# EHRPWM0_EPWM register map
Vendor: Texas Instruments
Peripheral module from a debugger description file (folder J7ES).
Registers are 16-bit, access per field, reset 0x0 unless marked. A register's access mark holds for its fields unless they carry their own. Offsets are as the file gives them; lines under a group give offsets from that group; [hi:lo] are bit positions; {n}, {i} and the like mark numbered series; 'fields as' and 'values as' point back to an identical list; <NAME> marks a mode.

## EHRPWM0_EPWM
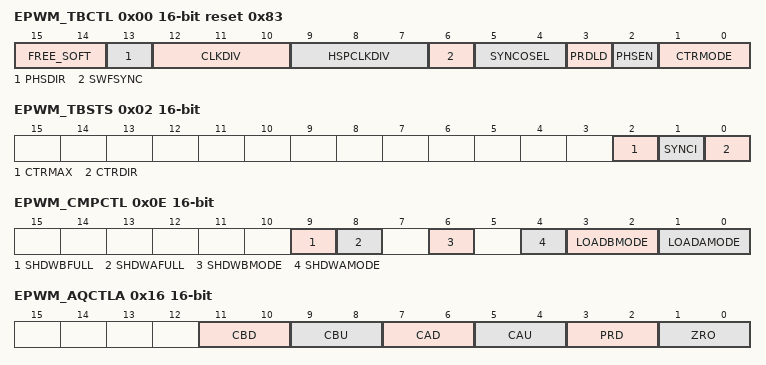
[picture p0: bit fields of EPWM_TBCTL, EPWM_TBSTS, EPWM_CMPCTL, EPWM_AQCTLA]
0x00 EPWM_TBCTL rw reset 0x83
  [15:14] FREE_SOFT, [13] PHSDIR, [12:10] CLKDIV, [9:7] HSPCLKDIV, [6] SWFSYNC, [5:4] SYNCOSEL, [3] PRDLD, [2] PHSEN, [1:0] CTRMODE
0x02 EPWM_TBSTS access not given
  [2] CTRMAX — (access RW1C)
  [1] SYNCI — (access RW1C)
  [0] CTRDIR ro
0x04 HRPWM_TBPHSHR
  [15:8] TBPHSH rw — Time-base phase high-resolution bits
0x06 EPWM_TBPHS rw — This register is only available on ePWM instances that include the high-resolution PWM (HRPWM) extension, otherwise, this location is reserved.
  [15:0] TBPHS — These bits set time-base counter phase of the selected ePWM relative to the time-base that is supplying the synchronization input signal [a] If
0x08 EPWM_TBCNT rw
0x0A EPWM_TBPRD rw
0x0E EPWM_CMPCTL
  [9] SHDWBFULL ro, [8] SHDWAFULL ro, [6] SHDWBMODE rw, [4] SHDWAMODE rw, [3:2] LOADBMODE rw, [1:0] LOADAMODE rw
0x10 HRPWM_CMPAHR — This register is only available on ePWM instances that include the high-resolution PWM (HRPWM) extension; otherwise, this location is reserved.
  [15:8] CMPAHR rw
0x12 EPWM_CMPA rw
0x14 EPWM_CMPB rw
0x16 EPWM_AQCTLA
  [11:10] CBD rw, [9:8] CBU rw, [7:6] CAD rw, [5:4] CAU rw, [3:2] PRD rw, [1:0] ZRO rw
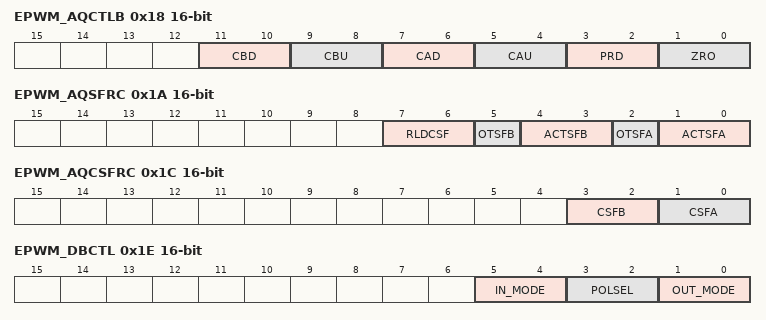
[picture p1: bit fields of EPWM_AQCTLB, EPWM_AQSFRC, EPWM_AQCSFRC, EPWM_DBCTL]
0x18 EPWM_AQCTLB
  fields as EPWM_AQCTLA
0x1A EPWM_AQSFRC access not given
  [7:6] RLDCSF rw
  [5] OTSFB — (access RW1C)
  [4:3] ACTSFB rw
  [2] OTSFA — (access RW1C)
  [1:0] ACTSFA rw
0x1C EPWM_AQCSFRC
  [3:2] CSFB rw, [1:0] CSFA rw
0x1E EPWM_DBCTL
  [5:4] IN_MODE rw, [3:2] POLSEL rw, [1:0] OUT_MODE rw
0x20 EPWM_DBRED
  [9:0] DEL rw — Rising Edge Delay Count. 10-bit counter.
0x22 EPWM_DBFED
  [9:0] DEL rw — Falling Edge Delay Count. 10-bit counter
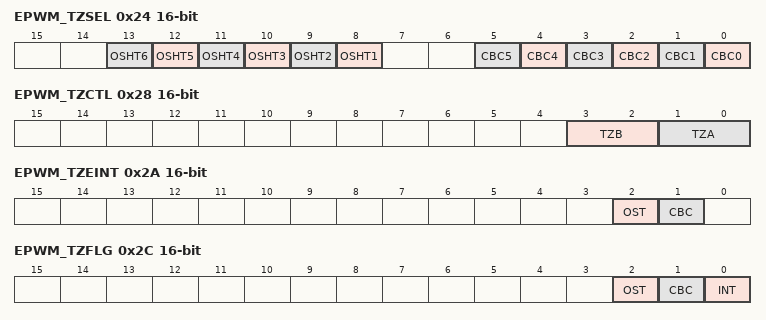
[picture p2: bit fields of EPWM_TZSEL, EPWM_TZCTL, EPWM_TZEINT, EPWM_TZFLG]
0x24 EPWM_TZSEL
  [n+7] OSHT{n} rw (n=1..6), [n] CBC{n} rw (n=0..5)
0x28 EPWM_TZCTL
  [3:2] TZB rw, [1:0] TZA rw
0x2A EPWM_TZEINT
  [2] OST rw — Trip-zone One-Shot Interrupt Enable 0h = Disable one-shot interrupt generation 1h = Enable Interrupt generation
  [1] CBC rw — Trip-zone Cycle-by-Cycle Interrupt Enable 0h = Disable cycle-by-cycle interrupt generation. 1h = Enable interrupt generation
0x2C EPWM_TZFLG ro
  [2] OST, [1] CBC, [0] INT
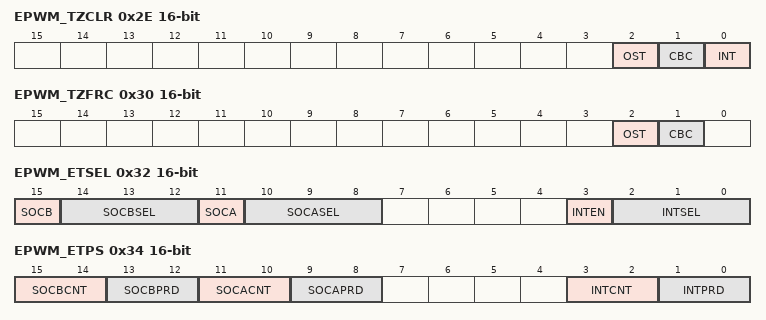
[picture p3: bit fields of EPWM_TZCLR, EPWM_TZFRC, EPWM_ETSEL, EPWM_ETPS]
0x2E EPWM_TZCLR
  [2] OST rw, [1] CBC rw, [0] INT rw
0x30 EPWM_TZFRC
  [2] OST rw, [1] CBC rw
0x32 EPWM_ETSEL
  [15] SOCB rw — Enable SOCB pulse when set to 1.
  [14:12] SOCBSEL rw — EPWMxSOCB Selection Options: 0h: Reserved 1h: Enable event time-base counter equal to zero (CNT_zero event). 2h: Enable event time-base counter equal to period (PRD_eq event). 3h: Reserved 4h: Enable event time-base counter equal to CMPA when the timer is incrementing (CMPA_eq_UC event). 5h: Enable event time-base counter equal to CMPA when the timer is decrementing (CMPA_eq_DC event). 6h: Enable event time-base counter equal to CMPB when the timer is incrementing (CMPB_eq_UC event). 7h: Enable event time-base counter equal to CMPB when the timer is decrementing (CMPB_eq_DC event).
  [11] SOCA rw — Enable SOCA pulse when set to 1.
  [10:8] SOCASEL rw — EPWMxSOCA Selection Options: 0h: Reserved 1h: Enable event time-base counter equal to zero (CNT_zero event). 2h: Enable event time-base counter equal to period (PRD_eq event). 3h: Reserved 4h: Enable event time-base counter equal to CMPA when the timer is incrementing (CMPA_eq_UC event). 5h: Enable event time-base counter equal to CMPA when the timer is decrementing (CMPA_eq_DC event). 6h: Enable event time-base counter equal to CMPB when the timer is incrementing (CMPB_eq_UC event). 7h: Enable event time-base counter equal to CMPB when the timer is decrementing (CMPB_eq_DC event).
  [3] INTEN rw
  [2:0] INTSEL rw
0x34 EPWM_ETPS
  [15:14] SOCBCNT ro — EPWMxSOCB Counter Register: These bits indicate how many selected events have occurred: 0h: No events 1h: 1 events 2h: 2 events 3h: 3 event
  [13:12] SOCBPRD rw — EPWMxSOCB Period Select: These bits select how many selected event need to occur before an SOCB pulse is generated: 0h: Disable counter 1h: Generate pulse on SOCBCNT = 1 (1st event) 2h: Generate pulse on SOCBCNT = 2 (2nd event) 3h: Generate pulse on SOCBCNT = 3 (3rd event)
  [11:10] SOCACNT ro — EPWMxSOCA Counter Register: These bits indicate how many selected events have occurred: 0h: No events 1h: 1 events 2h: 2 events 3h: 3 events
  [9:8] SOCAPRD rw — EPWMxSOCA Period Select: These bits select how many selected event need to occur before an SOCA pulse is generated: 0h: Disable counter 1h: Generate pulse on SOCACNT = 1 (1st event) 2h: Generate pulse on SOCACNT = 2 (2nd event) 3h: Generate pulse on SOCACNT = 3 (3rd event)
  [3:2] INTCNT ro
  [1:0] INTPRD rw
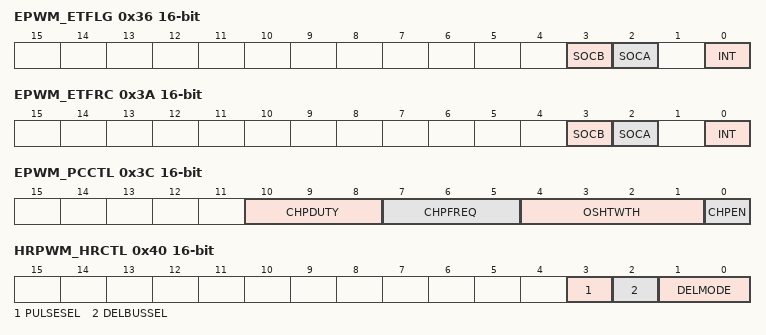
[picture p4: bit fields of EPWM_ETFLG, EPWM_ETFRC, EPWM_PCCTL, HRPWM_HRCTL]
0x36 EPWM_ETFLG ro
  [3] SOCB — Latched SOCB Flag Bit Status: 0h: Indicates no event occurred. 1h: Indicates that a start of conversion pulse was generated on EPWMxSOCB. Note: Unlike the INT flag bit, the EPWMxSOCB output will continue to pulse even if the flag bit is set.
  [2] SOCA — Latched SOCA Flag Bit Status: 0h: Indicates no event occurred. 1h: Indicates that a start of conversion pulse was generated on EPWMxSOCA. Note: Unlike the INT flag bit, the EPWMxSOCA output will continue to pulse even if the flag bit is set.
  [0] INT
0x38 EPWM_ETCLR ro
  [0] INT — ePWM Interrupt [EPWMx_INT] Flag Clear Bit
0x3A EPWM_ETFRC
  [3] SOCB rw — SOCB Flag Clear Bit: 0h: Writing a 0 has no effect. Always reads back a 0. 1h: Writing a 1 clears the EPWM_ETFLG[3] SOCB flag bit.
  [2] SOCA rw — SOCA Flag Clear Bit: 0h: Writing a 0 has no effect. Always reads back a 0. 1h: Writing a 1 clears the EPWM_ETFLG[2] SOCA flag bit.
  [0] INT rw
0x3C EPWM_PCCTL
  [10:8] CHPDUTY rw, [7:5] CHPFREQ rw, [4:1] OSHTWTH rw, [0] CHPEN rw
0x40 HRPWM_HRCTL — This register is only available on EPWM instances that include the high-resolution PWM (HRPWM) extension. Otherwise, this location is reserved.
  [3] PULSESEL rw
  [2] DELBUSSEL rw
  [1:0] DELMODE rw — Edge Mode Bits. Selects the edge of the PWM that is controlled by the micro-edge position (MEP) logic.
0x5C EPWM_PID 32-bit ro reset 0x44D10903 — The IP revision register is used by software to track features, bugs, and compatibility.
  [31:0] REVISION — TI internal data. Identifies revision of peripheral.
